# STM32F101xB register map
File version: 1.0
Registers are 32-bit, read-write, reset 0x0 unless marked. A register's access mark holds for its fields unless they carry their own. Offsets are from the block's base; lines under a group give offsets from that group; [hi:lo] are bit positions; {n}, {i} and the like mark numbered series; 'fields as' and 'values as' point back to an identical list; <NAME> marks a mode.

## Memory map
0x1FFFF800 OB — Option Bytes Registers
0x40000000 TIM2 — TIM Timers
0x40000400 TIM3 — TIM Timers
0x40000800 TIM4 — TIM Timers
0x40002800 RTC — Real-Time Clock
0x40002C00 WWDG — Window WATCHDOG
0x40003000 IWDG — Independent WATCHDOG
0x40003800 SPI2 — Serial Peripheral Interface
0x40004400 USART2 — Universal Synchronous Asynchronous Receiver Transmitter
0x40004800 USART3 — Universal Synchronous Asynchronous Receiver Transmitter
0x40005400 I2C1 — Inter Integrated Circuit Interface
0x40005800 I2C2 — Inter Integrated Circuit Interface
0x40006C00 BKP — Backup Registers
0x40007000 PWR — Power Control
0x40010000 AFIO — Alternate Function I/O
0x40010400 EXTI — External Interrupt/Event Controller
0x40010800 GPIOA — General Purpose I/O
0x40010C00 GPIOB — General Purpose I/O
0x40011000 GPIOC — General Purpose I/O
0x40011400 GPIOD — General Purpose I/O
0x40011800 GPIOE — General Purpose I/O
0x40012400 ADC1 — Analog to Digital Converter
0x40013000 SPI1 — Serial Peripheral Interface
0x40013800 USART1 — Universal Synchronous Asynchronous Receiver Transmitter
0x40020000 DMA1
0x40021000 RCC — Reset and Clock Control
0x40022000 FLASH — FLASH Registers
0x40023000 CRC — CRC calculation unit
0xE0042000 DBGMCU — Debug MCU

## Interrupts
0 WWDG — Window WatchDog Interrupt
3 RTC — RTC global Interrupt
4 FLASH — FLASH global Interrupt
5 RCC — RCC global Interrupt
6 EXTI0 (EXTI) — EXTI Line0 Interrupt
7 EXTI1 (EXTI) — EXTI Line1 Interrupt
8 EXTI2 (EXTI) — EXTI Line2 Interrupt
9 EXTI3 (EXTI) — EXTI Line3 Interrupt
10 EXTI4 (EXTI) — EXTI Line4 Interrupt
11 DMA1_Channel1 (DMA1) — DMA1 Channel 1 global Interrupt
12 DMA1_Channel2 (DMA1) — DMA1 Channel 2 global Interrupt
13 DMA1_Channel3 (DMA1) — DMA1 Channel 3 global Interrupt
14 DMA1_Channel4 (DMA1) — DMA1 Channel 4 global Interrupt
15 DMA1_Channel5 (DMA1) — DMA1 Channel 5 global Interrupt
16 DMA1_Channel6 (DMA1) — DMA1 Channel 6 global Interrupt
17 DMA1_Channel7 (DMA1) — DMA1 Channel 7 global Interrupt
18 ADC1 — ADC1 global Interrupt
23 EXTI9_5 (EXTI) — External Line[9:5] Interrupts
28 TIM2 — TIM2 global Interrupt
29 TIM3 — TIM3 global Interrupt
30 TIM4 — TIM4 global Interrupt
31 I2C1_EV (I2C1) — I2C1 Event Interrupt
32 I2C1_ER (I2C1) — I2C1 Error Interrupt
33 I2C2_EV (I2C2) — I2C2 Event Interrupt
34 I2C2_ER (I2C2) — I2C2 Error Interrupt
35 SPI1 — SPI1 global Interrupt
36 SPI2 — SPI2 global Interrupt
37 USART1 — USART1 global Interrupt
38 USART2 — USART2 global Interrupt
39 USART3 — USART3 global Interrupt
40 EXTI15_10 (EXTI) — External Line[15:10] Interrupts
41 RTC_Alarm (RTC) — RTC Alarm through EXTI Line Interrupt

## OB — Option Bytes Registers
Base 0x1FFFF800
0x00 RDP 16-bit
0x02 USER 16-bit
0x04 Data0 16-bit
0x06 Data1 16-bit
{0x8+2i} WRP{i} 16-bit (i=0..3)

## RTC — Real-Time Clock
Base 0x40002800
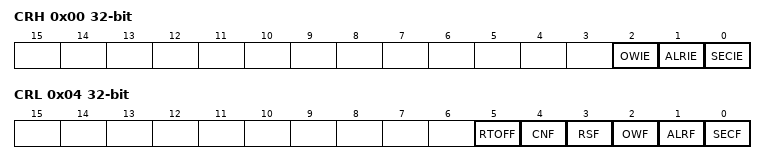
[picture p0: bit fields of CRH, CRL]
0x00 CRH
  [2] OWIE — OverfloW Interrupt Enable
  [1] ALRIE — Alarm Interrupt Enable
  [0] SECIE — Second Interrupt Enable
0x04 CRL
  [5] RTOFF — RTC operation OFF
  [4] CNF — Configuration Flag
  [3] RSF — Registers Synchronized Flag
  [2] OWF — OverfloW Flag
  [1] ALRF — Alarm Flag
  [0] SECF — Second Flag
0x08 PRLH
  [3:0] PRL — RTC Prescaler Reload Value High
0x0C PRLL
  [15:0] PRL — RTC Prescaler Reload Value Low
0x10 DIVH
  [3:0] RTC_DIV — RTC Clock Divider High
0x14 DIVL
  [15:0] RTC_DIV — RTC Clock Divider Low
0x18 CNTH
  [15:0] RTC_CNT — RTC Counter High
0x1C CNTL
  [15:0] RTC_CNT — RTC Counter Low
0x20 ALRH
  [15:0] RTC_ALR — RTC Alarm High
0x24 ALRL
  [15:0] RTC_ALR — RTC Alarm Low

## WWDG — Window WATCHDOG
Base 0x40002C00
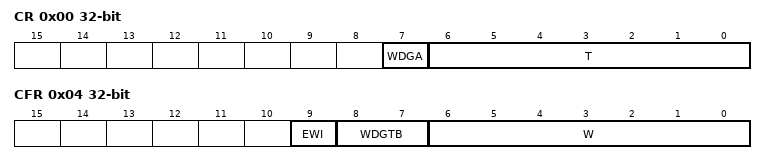
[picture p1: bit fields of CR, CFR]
0x00 CR — WWDG Control register
  [7] WDGA — Activation bit
  [6:0] T — T[6:0] bits (7-Bit counter (MSB to LSB))
0x04 CFR — WWDG Configuration register
  [9] EWI — Early Wakeup Interrupt
  [8:7] WDGTB — WDGTB[1:0] bits (Timer Base)
    0=PRESCALER_1 (WWDG counter clock = (PCLK1/4096)/1); 1=PRESCALER_2 (WWDG counter clock = (PCLK1/4096)/2); 2=PRESCALER_4 (WWDG counter clock = (PCLK1/4096)/4); 3=PRESCALER_8 (WWDG counter clock = (PCLK1/4096)/8)
  [6:0] W — W[6:0] bits (7-bit window value)
0x08 SR — WWDG Status register
  [0] EWIF — Early Wakeup Interrupt Flag
